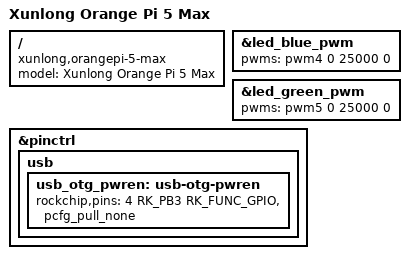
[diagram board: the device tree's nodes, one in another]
// SPDX-License-Identifier: (GPL-2.0+ OR MIT)

/dts-v1/;

#include <dt-bindings/gpio/gpio.h>
#include <dt-bindings/pinctrl/rockchip.h>
#include <dt-bindings/soc/rockchip,vop2.h>
#include "rk3588-orangepi-5-compact.dtsi"

/ {
	model = "Xunlong Orange Pi 5 Max";
	compatible = "xunlong,orangepi-5-max", "rockchip,rk3588";

};

&led_blue_pwm {
	pwms = <&pwm4 0 25000 0>;
};

&led_green_pwm {
	pwms = <&pwm5 0 25000 0>;
};

&pinctrl {

	usb {
		usb_otg_pwren: usb-otg-pwren {
			rockchip,pins = <4 RK_PB3 RK_FUNC_GPIO &pcfg_pull_none>;
		};
	};
};
